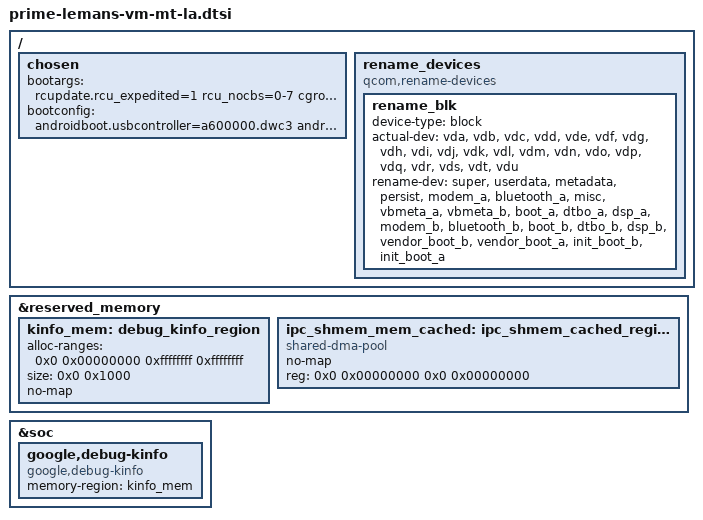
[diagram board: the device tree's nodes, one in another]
// SPDX-License-Identifier: BSD-3-Clause
/*
 * Copyright (c) Qualcomm Technologies, Inc. and/or its subsidiaries.
 */

/ {
	chosen {
		bootargs = "rcupdate.rcu_expedited=1 rcu_nocbs=0-7 cgroup.memory=nokmem,nosocket kpti=0 ufshcd-core.use_mcq_mode=n arm64.nopauth kasan=off msm_show_resume_irq.debug_mask=1";
		bootconfig = "androidboot.usbcontroller=a600000.dwc3 androidboot.fstab_suffix=gen4.qcom androidboot.dtbo_idx=2";
	};

	rename_devices: rename_devices {
		compatible = "qcom,rename-devices";
		rename_blk: rename_blk {
			device-type = "block";
			actual-dev = "vda", "vdb", "vdc",
					"vdd", "vde", "vdf",
					"vdg", "vdh", "vdi",
					"vdj", "vdk", "vdl",
					"vdm", "vdn", "vdo",
					"vdp", "vdq", "vdr",
					"vds", "vdt", "vdu";
			rename-dev = "super", "userdata", "metadata",
					"persist", "modem_a","bluetooth_a",
					"misc", "vbmeta_a", "vbmeta_b",
					"boot_a", "dtbo_a", "dsp_a",
					"modem_b", "bluetooth_b", "boot_b",
					"dtbo_b", "dsp_b", "vendor_boot_b",
					"vendor_boot_a", "init_boot_b", "init_boot_a";
		};
	};
};

&reserved_memory {
	kinfo_mem: debug_kinfo_region {
		alloc-ranges = <0x0 0x00000000 0xffffffff 0xffffffff>;
		size = <0x0 0x1000>;
		no-map;
	};

	ipc_shmem_mem_cached: ipc_shmem_cached_region {
		compatible = "shared-dma-pool";
		no-map;
		reg = <0x0 0x00000000 0x0 0x00000000>;
	};
};

&soc {
	google,debug-kinfo {
		compatible = "google,debug-kinfo";
		memory-region = <&kinfo_mem>;
	};
};
